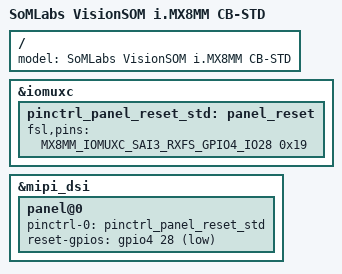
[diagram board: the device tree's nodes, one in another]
// SPDX-License-Identifier: GPL-2.0-or-later
/*
 * Copyright 2020 SomLabs
 *
 */

#include "visionsom-8mm-cb-std.dtsi"
#include "visionsom-8mm-cb-mipi.dtsi"

/ {
    model = "SoMLabs VisionSOM i.MX8MM CB-STD";
};

&iomuxc {

    pinctrl_panel_reset_std: panel_reset {
        fsl,pins = <
            MX8MM_IOMUXC_SAI3_RXFS_GPIO4_IO28       0x19
        >;
    };

};

&mipi_dsi {
    panel@0 {
        pinctrl-names = "default";
        pinctrl-0 = <&pinctrl_panel_reset_std>;
        reset-gpios = <&gpio4 28 GPIO_ACTIVE_LOW>;
    };
};
